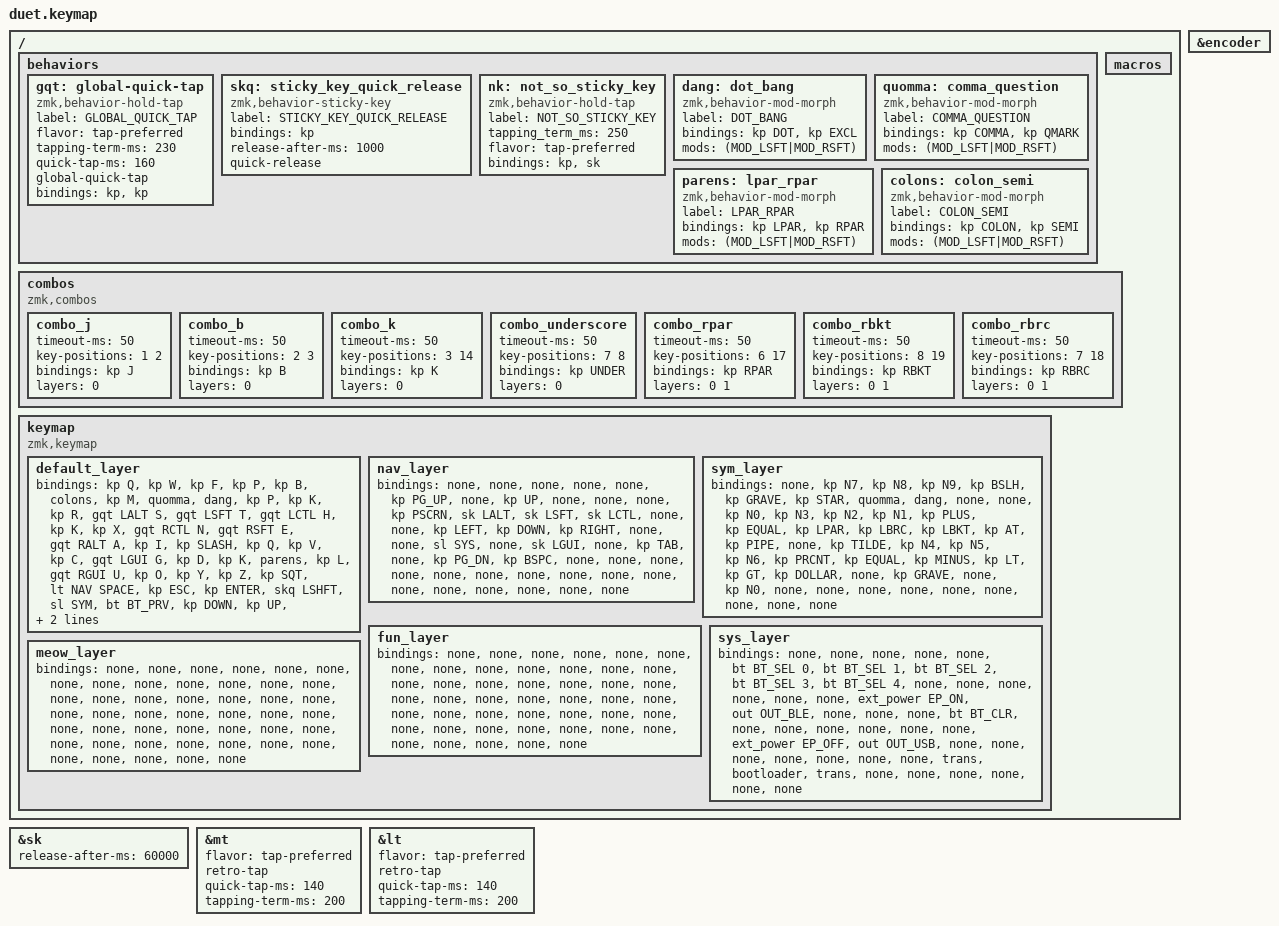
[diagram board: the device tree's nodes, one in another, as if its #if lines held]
/*
 * Copyright (c) 2020 The ZMK Contributors
 *
 * SPDX-License-Identifier: MIT
 */

#include <behaviors.dtsi>
#include <dt-bindings/zmk/keys.h>
#include <dt-bindings/zmk/bt.h>
#include <dt-bindings/zmk/outputs.h>
#include <dt-bindings/zmk/ext_power.h>

#define BSE 0
#define NAV 1
#define SYM 2
#define FUN 3
#define SYS 4

#define KEYS_L 0 1 2 3 4 10 11 12 13 14 15 22 23 24 25 26 27  // left-hand keys
#define KEYS_R 5 6 7 8 9 16 17 18 19 20 21 28 29 30 31 32 33  // right-hand keys
#define THUMBS 34 35 36 37 38 39

#define TAPPING_TERM 210
#define SHIFT_TAP    170
#define QUICK_TAP    130

#define HYP(KEY) LG(LA(LS(LC(key))))
#define MEH(KEY) LA(LS(LC(key)))

&sk {
  release-after-ms = <60000>;
};

&mt {
    flavor = "tap-preferred";
    retro-tap;
    quick-tap-ms = <140>;
    tapping-term-ms = <200>;
};

&lt {
    flavor = "tap-preferred";
    retro-tap;
    quick-tap-ms = <140>;
    tapping-term-ms = <200>;
};

&encoder {
    status = "okay";
};

/ {
    behaviors {
        // modifier stuff //
        gqt: global-quick-tap {
            compatible = "zmk,behavior-hold-tap";
            label = "GLOBAL_QUICK_TAP";
            #binding-cells = <2>;
            flavor = "tap-preferred";
            tapping-term-ms = <230>;
            quick-tap-ms = <160>;
            global-quick-tap;
            bindings = <&kp>, <&kp>;
	    };

        skq: sticky_key_quick_release {
            compatible = "zmk,behavior-sticky-key";
            label = "STICKY_KEY_QUICK_RELEASE";
            #binding-cells = <1>;
            bindings = <&kp>;
            release-after-ms = <1000>;
            quick-release;
        };

        // Sticky key on tap, normal key on hold
    	// Useful for modifier-clicking without the modifier remaining active
    	nk: not_so_sticky_key {
            compatible = "zmk,behavior-hold-tap";
            label = "NOT_SO_STICKY_KEY";
            #binding-cells = <2>;
            tapping_term_ms = <250>;
            flavor = "tap-preferred";
            bindings = <&kp>, <&sk>;
        };


        // custom keys //
        dang: dot_bang {
            compatible = "zmk,behavior-mod-morph";
            label = "DOT_BANG";
            #binding-cells = <0>;
            bindings = <&kp DOT>, <&kp EXCL>;
            mods = <(MOD_LSFT|MOD_RSFT)>;
        };

        quomma: comma_question {
            compatible = "zmk,behavior-mod-morph";
            label = "COMMA_QUESTION";
            #binding-cells = <0>;
            bindings = <&kp COMMA>, <&kp QMARK>;
            mods = <(MOD_LSFT|MOD_RSFT)>;
        };

        parens: lpar_rpar {
            compatible = "zmk,behavior-mod-morph";
            label = "LPAR_RPAR";
            #binding-cells = <0>;
            bindings = <&kp LPAR>, <&kp RPAR>;
            mods = <(MOD_LSFT|MOD_RSFT)>;
        };

        colons: colon_semi {
            compatible = "zmk,behavior-mod-morph";
            label = "COLON_SEMI";
            #binding-cells = <0>;
            bindings = <&kp COLON>, <&kp SEMI>;
            mods = <(MOD_LSFT|MOD_RSFT)>;
        };
	
    };

    macros {
        // m_arrow: m_arrow {
        //     compatible = "zmk,behavior-macro";
        //     #binding-cells = <0>;
        //     bindings = <&kp EQUAL &kp GT>;
        // };
    };

    combos {
        compatible = "zmk,combos";

	combo_j {
            timeout-ms = <50>;
            key-positions = <1 2>;
            bindings = <&kp J>;
            layers = <0>;
        };

	combo_b {
            timeout-ms = <50>;
            key-positions = <2 3>;
            bindings = <&kp B>;
            layers = <0>;
        };

	combo_k {
            timeout-ms = <50>;
            key-positions = <3 14>;
            bindings = <&kp K>;
            layers = <0>;
        };

	combo_underscore {
		timeout-ms = <50>;
		key-positions = <7 8>;
		bindings = <&kp UNDER>;
		layers = <0>;
	};

	combo_rpar {
            timeout-ms = <50>;
            key-positions = <6 17>;
            bindings = <&kp RPAR>;
            layers = <0 1>;
        };

	combo_rbkt {
            timeout-ms = <50>;
            key-positions = <8 19>;
            bindings = <&kp RBKT>;
            layers = <0 1>;
        };

	combo_rbrc {
            timeout-ms = <50>;
            key-positions = <7 18>;
            bindings = <&kp RBRC>;
            layers = <0 1>;
        };
    };

    keymap {
        compatible = "zmk,keymap";

        default_layer {
            bindings = <
                           &kp Q        &kp W        &kp F         &kp P         &kp B            &colons    &kp M         &quomma       &dang        &kp P
                &kp K      &kp R        &gqt LALT S  &gqt LSFT T   &gqt LCTL H   &kp K            &kp X      &gqt RCTL N   &gqt RSFT E   &gqt RALT A  &kp I      &kp SLASH
                &kp Q      &kp V        &kp C        &gqt LGUI G   &kp D         &kp K            &parens    &kp L         &gqt RGUI U   &kp O        &kp Y      &kp Z
                                                     &kp SQT       &lt NAV SPACE &kp ESC          &kp ENTER  &skq LSHFT    &sl SYM
                &bt BT_PRV  &kp DOWN  &kp UP  &bt BT_NXT  &bootloader                                                                        &none
            >;

            sensor-bindings = <&inc_dec_kp C_VOL_UP C_VOL_DN>;
        };

        nav_layer {
            bindings = <
                          &none     &none     &none     &none     &none           &kp PG_UP &none     &kp UP    &none     &none
                &none     &kp PSCRN &sk LALT  &sk LSFT  &sk LCTL  &none           &none     &kp LEFT  &kp DOWN  &kp RIGHT &none     &none
                &sl SYS   &none     &sk LGUI  &none     &kp TAB   &none           &kp PG_DN &kp BSPC  &none     &none     &none     &none
                                              &none     &none     &none           &none     &none     &none
                &none  &none  &none  &none  &none                                                                         &none
            >;
        };

        sym_layer {
            bindings = <
                          &none     &kp N7    &kp N8    &kp N9    &kp BSLH        &kp GRAVE &kp STAR  &quomma   &dang     &none
                &none     &kp N0    &kp N3    &kp N2    &kp N1    &kp PLUS        &kp EQUAL &kp LPAR  &kp LBRC  &kp LBKT  &kp AT     &kp PIPE
                &none     &kp TILDE &kp N4    &kp N5    &kp N6    &kp PRCNT       &kp EQUAL &kp MINUS &kp LT    &kp GT    &kp DOLLAR &none
                                              &kp GRAVE &none     &kp N0          &none     &none     &none
                &none  &none  &none  &none  &none                                                                         &none
            >;
        };

        fun_layer {
            bindings = <
                          &none     &none     &none     &none     &none           &none     &none     &none     &none     &none
                &none     &none     &none     &none     &none     &none           &none     &none     &none     &none     &none     &none
                &none     &none     &none     &none     &none     &none           &none     &none     &none     &none     &none     &none
                                              &none     &none     &none           &none     &none     &none
                &none  &none  &none  &none  &none                                                                         &none
            >;
        };

        sys_layer {
            bindings = <
                          &none     &none     &none     &none     &none           &bt BT_SEL 0       &bt BT_SEL 1  &bt BT_SEL 2  &bt BT_SEL 3  &bt BT_SEL 4
                &none     &none     &none     &none     &none     &none           &ext_power EP_ON   &out OUT_BLE  &none         &none         &none           &bt BT_CLR
                &none     &none     &none     &none     &none     &none           &ext_power EP_OFF  &out OUT_USB  &none         &none         &none           &none
                                                &none     &none     &none       &trans      &bootloader     &trans
                &none  &none  &none  &none  &none                                                                                              &none
            >;
        };

// keymap drawer stub layers
#ifdef KEYMAP_DRAWER
        meow_layer {
            bindings = <
                          &none     &none     &none     &none     &none           &none     &none     &none     &none     &none
                &none     &none     &none     &none     &none     &none           &none     &none     &none     &none     &none     &none
                &none     &none     &none     &none     &none     &none           &none     &none     &none     &none     &none     &none
                                              &none     &none     &none           &none     &none     &none
                &none  &none  &none  &none  &none                                                                         &none
            >;
        };
#endif

    };
};
